VERSION ""

NS_ :

BS_:
BU_: SENSOR_MODULE E_BOX PI VESC Throttle
BO_ 2147485696 PORT_SONAR: 8 SENSOR_MODULE
   SG_ PORT_SONAR_HEIGHT : 1|16@0+ (1,0) [0|6000] "mm" PI

BO_ 2147485697 STARBOARD_SONAR: 8 SENSOR_MODULE
   SG_ STARBOARD_SONAR_HEIGHT : 1|16@0+ (1,0) [0|6000] "mm" PI

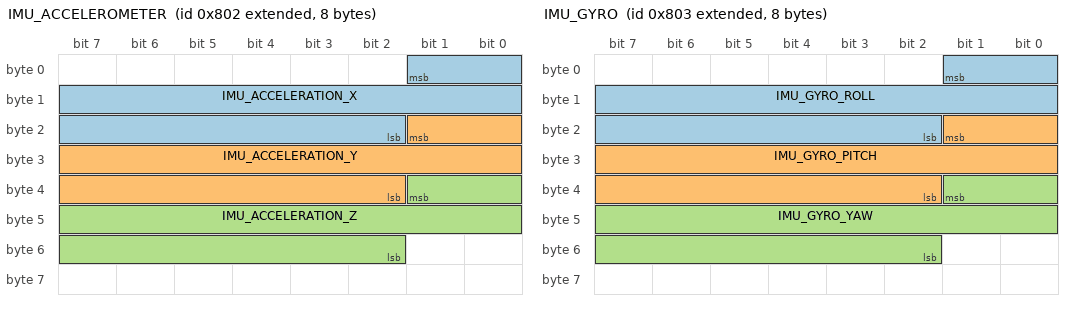
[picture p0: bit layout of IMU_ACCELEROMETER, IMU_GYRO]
BO_ 2147485698 IMU_ACCELEROMETER: 8 SENSOR_MODULE
   SG_ IMU_ACCELERATION_X : 1|16@0- (0.001,0) [-50|50] "" PI
   SG_ IMU_ACCELERATION_Y : 17|16@0- (0.001,0) [-50|50] "" PI
   SG_ IMU_ACCELERATION_Z : 33|16@0- (0.001,0) [-50|50] "" PI

BO_ 2147485699 IMU_GYRO: 8 SENSOR_MODULE
   SG_ IMU_GYRO_ROLL : 1|16@0- (0.001,0) [-250|250] "" PI
   SG_ IMU_GYRO_PITCH : 17|16@0- (0.001,0) [-250|250] "" PI
   SG_ IMU_GYRO_YAW : 33|16@0- (0.001,0) [-250|250] "" PI

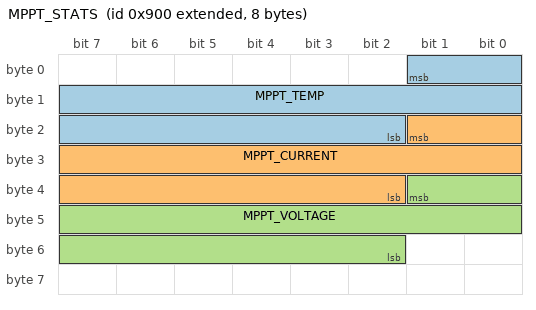
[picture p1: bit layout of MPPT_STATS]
BO_ 2147485952 MPPT_STATS: 8 E_BOX
   SG_ MPPT_TEMP : 1|16@0- (0.01,0) [-100|100] "C" PI
   SG_ MPPT_CURRENT : 17|16@0+ (0.1,0) [0|1] "A" PI
   SG_ MPPT_VOLTAGE : 33|16@0+ (0.1,0) [0|1] "V" PI

BO_ 2147485953 PMU: 8 E_BOX
   SG_ PMU_TEMP : 1|16@0- (0.01,0) [-100|100] "C" PI

BO_ 2147485954 AFT_SONAR: 8 E_BOX
   SG_ AFT_SONAR_HEIGHT : 1|16@0+ (1,0) [0|6000] "mm" PI

BO_ 2147485700 IMU_TEMP: 8 SENSOR_MODULE
   SG_ IMU_TEMPERATURE : 1|16@0+ (0.01,0) [-30|100] "C" PI

BO_ 22 SETDUTY: 4 Throttle
   SG_ SET_DUTY_signed : 7|32@0- (0.001,0) [-100|100] "" Throttle

BA_DEF_ BO_ "GenMsgBackgroundColor" STRING ;
BA_DEF_ BO_ "GenMsgForegroundColor" STRING ;
BA_DEF_ BO_ "filterlabeling" INT 0 0;
BA_DEF_ BO_ "filterlabeling" INT 0 0;
BA_DEF_DEF_ "GenMsgBackgroundColor" "#ffffff";
BA_DEF_DEF_ "GenMsgForegroundColor" "#000000";
BA_DEF_DEF_ "filterlabeling" 1;
